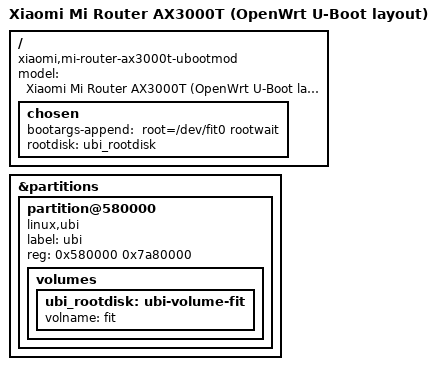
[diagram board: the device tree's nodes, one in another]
// SPDX-License-Identifier: GPL-2.0-or-later OR MIT

/dts-v1/;
#include "mt7981b-xiaomi-mi-router-ax3000t-common.dtsi"

/ {
	model = "Xiaomi Mi Router AX3000T (OpenWrt U-Boot layout)";
	compatible = "xiaomi,mi-router-ax3000t-ubootmod", "mediatek,mt7981";

	chosen {
		bootargs-append = " root=/dev/fit0 rootwait";
		rootdisk = <&ubi_rootdisk>;
	};
};

&partitions {
	partition@580000 {
		label = "ubi";
		reg = <0x580000 0x7a80000>;
				compatible = "linux,ubi";

				volumes {
					ubi_rootdisk: ubi-volume-fit {
						volname = "fit";
					};
				};
	};
};
